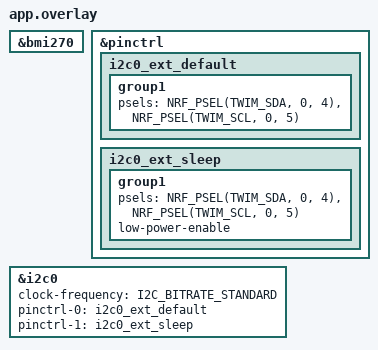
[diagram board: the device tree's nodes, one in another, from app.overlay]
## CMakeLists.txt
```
# Thingy:53 gait sensor node — integration firmware.
# Each sensor/radio module is compiled only when its Kconfig switch is on (see Kconfig).

cmake_minimum_required(VERSION 3.20.0)
find_package(Zephyr REQUIRED HINTS $ENV{ZEPHYR_BASE})
project(gait_node)

target_include_directories(app PRIVATE src src/plantar)

target_sources(app PRIVATE src/main.c)

target_sources_ifdef(CONFIG_GAIT_IMU app PRIVATE src/imu/imu.c)
target_sources_ifdef(CONFIG_GAIT_PLANTAR app PRIVATE src/plantar/fsr402.c)
target_sources_ifdef(CONFIG_GAIT_BLE app PRIVATE src/ble/gait_ble.c)
```

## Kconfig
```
# Module switches for the gait node. Turn a module off in prj.conf if it is not ready;
# the rest of the firmware still builds and runs.

menu "Gait node modules"

config GAIT_IMU
	bool "BMI270 IMU module (src/imu)"
	default y
	select SENSOR

config GAIT_IMU_RATE_HZ
	int "IMU sample rate (Hz)"
	default 100
	depends on GAIT_IMU

config GAIT_PLANTAR
	bool "FSR 402 plantar pressure module via Adafruit ADS7128 (I2C)"
	default n
	depends on I2C
	help
	  Enable the six-channel FSR402 interface using the Adafruit ADS7128
	  8-channel, 12-bit ADC over the dedicated external I2C bus.

config GAIT_PLANTAR_RATE_HZ
	int "Plantar sample rate (Hz)"
	default 50
	depends on GAIT_PLANTAR

config GAIT_BLE
	bool "BLE streaming to the i.MX95 (src/ble)"
	default n
	help
	  Off until protocol/BLE_GAIT_PROTOCOL.md is agreed. When off, samples
	  are printed to the USB serial console instead.

endmenu

source "Kconfig.zephyr"
```

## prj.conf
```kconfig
# Console over USB
CONFIG_STDOUT_CONSOLE=y
CONFIG_CBPRINTF_FP_SUPPORT=y

# Modules
CONFIG_GAIT_IMU=y
CONFIG_GAIT_PLANTAR=y
CONFIG_GAIT_BLE=n

# ADS7128 communicates over I2C (not the nRF5340 internal SAADC).
CONFIG_I2C=y

# Needed by the BMI270 sensor driver
CONFIG_SENSOR=y
# Needed by the BLE module. Uncomment with CONFIG_GAIT_BLE=y.
# CONFIG_BT=y
# CONFIG_BT_PERIPHERAL=y
# CONFIG_BT_DEVICE_NAME="GaitNode"
```

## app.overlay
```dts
/* Thingy:53 gait_node overlay
 *
 * BMI270 remains enabled on the board's existing SPI bus.
 *
 * ADS7128 uses a dedicated external I2C bus on the Thingy:53 expansion pins:
 *   P0.04 = EXP_BOARD_PIN1 = SDA
 *   P0.05 = EXP_BOARD_PIN2 = SCL
 *
 * The ADS7128 board is left at its factory I2C address 0x10.
 * This is safe here because this overlay uses i2c0 on P0.04/P0.05,
 * not the Thingy:53 onboard-sensor i2c1 bus (which already has BMM150 at 0x10).
 */
#include <zephyr/dt-bindings/pinctrl/nrf-pinctrl.h>

/* IMU owner: BMI270 on SPI, unchanged. */
&bmi270 {
	status = "okay";
};

/* Dedicated external I2C bus for the ADS7128 breakout. */
&pinctrl {
	i2c0_ext_default: i2c0_ext_default {
		group1 {
			psels = <NRF_PSEL(TWIM_SDA, 0, 4)>,
				<NRF_PSEL(TWIM_SCL, 0, 5)>;
		};
	};

	i2c0_ext_sleep: i2c0_ext_sleep {
		group1 {
			psels = <NRF_PSEL(TWIM_SDA, 0, 4)>,
				<NRF_PSEL(TWIM_SCL, 0, 5)>;
			low-power-enable;
		};
	};
};

&i2c0 {
	status = "okay";
	clock-frequency = <I2C_BITRATE_STANDARD>;
	pinctrl-0 = <&i2c0_ext_default>;
	pinctrl-1 = <&i2c0_ext_sleep>;
	pinctrl-names = "default", "sleep";
};
```

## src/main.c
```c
#include <stdio.h>
#include <stdint.h>
#include <stdbool.h>

#include <zephyr/kernel.h>
#include <zephyr/device.h>
#include <zephyr/drivers/sensor.h>
#include <zephyr/drivers/uart.h>

#include "plantar/fsr402.h"

int main(void)
{
    /* BMI270 IMU - Kaan's original sensor approach */
    const struct device *const dev =
        DEVICE_DT_GET_ONE(bosch_bmi270);

    struct sensor_value acc[3], gyr[3];
    struct sensor_value full_scale;
    struct sensor_value sampling_freq;
    struct sensor_value oversampling;

    /* ADS7128 / FSR402 - six channels */
    uint16_t fsr_raw[FSR402_CHANNEL_COUNT];
    bool fsr_ready = false;

    uint32_t dtr = 0;
    const struct device *uart =
        DEVICE_DT_GET(DT_CHOSEN(zephyr_console));

    /* Wait for USB serial host */
    for (int i = 0; i < 300 && !dtr; i++) {
        uart_line_ctrl_get(uart, UART_LINE_CTRL_DTR, &dtr);
        k_msleep(100);
    }
    k_msleep(500);

    printf("\n=== GAIT NODE STARTING ===\n");

    /* Initialize BMI270 */
    if (!device_is_ready(dev)) {
        printf("BMI270 device is not ready\n");
    } else {
        printf("BMI270 device ready: %s\n", dev->name);

        /* Accelerometer settings */
        full_scale.val1 = 2;
        full_scale.val2 = 0;

        sampling_freq.val1 = 100;
        sampling_freq.val2 = 0;

        oversampling.val1 = 1;
        oversampling.val2 = 0;

        sensor_attr_set(dev, SENSOR_CHAN_ACCEL_XYZ,
                        SENSOR_ATTR_FULL_SCALE, &full_scale);

        sensor_attr_set(dev, SENSOR_CHAN_ACCEL_XYZ,
                        SENSOR_ATTR_OVERSAMPLING, &oversampling);

        sensor_attr_set(dev, SENSOR_CHAN_ACCEL_XYZ,
                        SENSOR_ATTR_SAMPLING_FREQUENCY,
                        &sampling_freq);

        /* Gyroscope settings */
        full_scale.val1 = 500;
        full_scale.val2 = 0;

        sensor_attr_set(dev, SENSOR_CHAN_GYRO_XYZ,
                        SENSOR_ATTR_FULL_SCALE, &full_scale);

        sensor_attr_set(dev, SENSOR_CHAN_GYRO_XYZ,
                        SENSOR_ATTR_OVERSAMPLING, &oversampling);

        sensor_attr_set(dev, SENSOR_CHAN_GYRO_XYZ,
                        SENSOR_ATTR_SAMPLING_FREQUENCY,
                        &sampling_freq);
    }

    /* Initialize ADS7128 / FSR402 */
    printf("\n=== FSR402 ADS7128 initialization ===\n");

    if (fsr402_init() == 0) {
        fsr_ready = true;
        printf("FSR402 ADS7128 initialized\n");
    } else {
        printf("FSR402 ADS7128 initialization failed\n");
    }

    printf("\n=== GAIT NODE SAMPLING STARTED ===\n");

    while (1) {
        k_msleep(10);

        /* Read BMI270 */
        if (device_is_ready(dev)) {
            int rc = sensor_sample_fetch(dev);

            if (rc == 0) {
                rc = sensor_channel_get(
                    dev, SENSOR_CHAN_ACCEL_XYZ, acc);

                if (rc == 0) {
                    rc = sensor_channel_get(
                        dev, SENSOR_CHAN_GYRO_XYZ, gyr);
                }
            }

            if (rc == 0) {
                printf(
                    "IMU,AX=%d.%06d,AY=%d.%06d,AZ=%d.%06d,"
                    "GX=%d.%06d,GY=%d.%06d,GZ=%d.%06d\n",
                    acc[0].val1, acc[0].val2,
                    acc[1].val1, acc[1].val2,
                    acc[2].val1, acc[2].val2,
                    gyr[0].val1, gyr[0].val2,
                    gyr[1].val1, gyr[1].val2,
                    gyr[2].val1, gyr[2].val2
                );
            } else {
                printf("IMU read failed: rc=%d\n", rc);
            }
        }

        /* Read six FSR402 channels through ADS7128 */
        if (fsr_ready) {
            int rc = fsr402_read_all(fsr_raw);

            if (rc == 0) {
                printf(
                    "FSR,t_ms=%u,LH=%u,LB=%u,LT=%u,"
                    "RH=%u,RB=%u,RT=%u\n",
                    k_uptime_get_32(),
                    fsr_raw[0], fsr_raw[1], fsr_raw[2],
                    fsr_raw[3], fsr_raw[4], fsr_raw[5]
                );
            } else {
                printf("FSR read failed: rc=%d\n", rc);
            }
        }
    }

    return 0;
}
```
